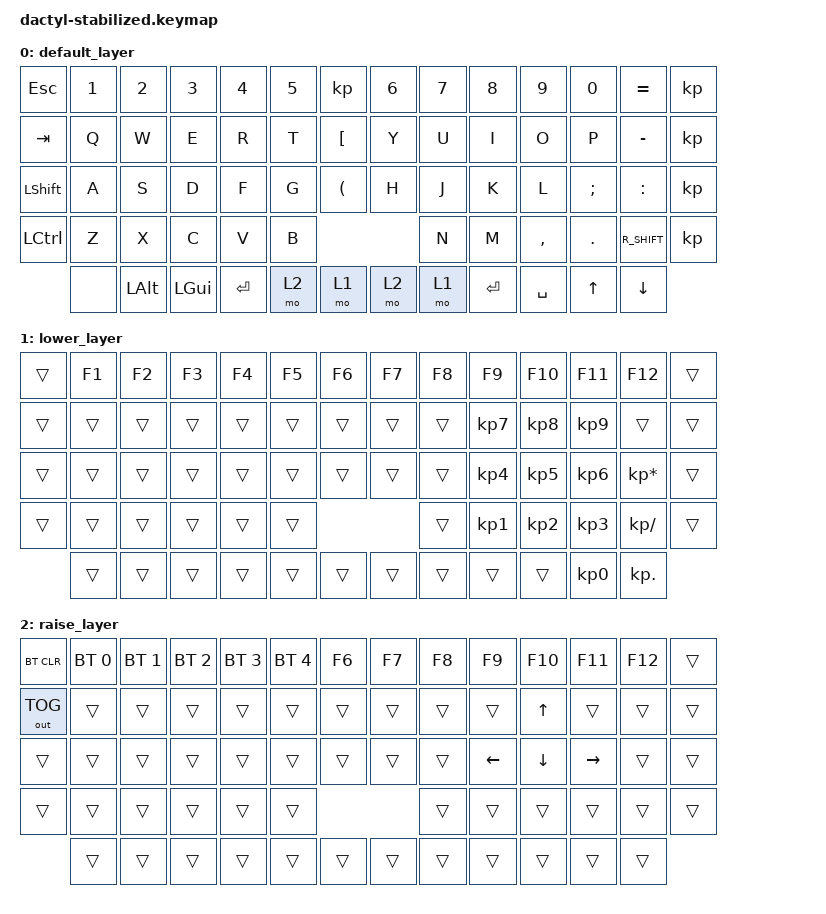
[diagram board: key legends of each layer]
/*
 * Copyright (c) 2020 The ZMK Contributors
 *
 * SPDX-License-Identifier: MIT
 */

 #include <behaviors.dtsi>
 #include <dt-bindings/zmk/keys.h>
 #include <dt-bindings/zmk/bt.h>
 #include <dt-bindings/zmk/outputs.h>
 
 / {
     keymap {
         compatible = "zmk,keymap";
 
         // TODO: SWAP SHIFTED KEYS SOMEHOW
         default_layer {
 // ------------------------------------------------------------------------------------------------------------
 // |  ESC  |  1  |  2  |   3  |   4   |   5   |       |  |   6   |   7   |  8    |  9    |  0   |   =   |       |
 // |  TAB  |  Q  |  W  |   E  |   R   |   T   |       |  |   Y   |   U   |  I    |  O    |  P   |   -   |       |
 // | SHIFT |  A  |  S  |   D  |   F   |   G   |       |  |   H   |   J   |  K    |  L    |  ;   |   '   |       |
 // |  CTRL |  Z  |  X  |   C  |   V   |   B   |       |  |   N   |   M   |  ,    |  .    |  /   | Shift |       |
 //         | LEFT|RIGHT| BSPC |  DEL  |       |       |  | RAISE | LOWER | ENTER | SPACE |  UP  |   DO  |

 bindings = <
 &kp ESC    &kp 1    &kp 2    &kp 3    &kp 4      &kp 5     &kp                &kp 6       &kp 7     &kp 8     &kp 9     &kp 0       &kp EQUAL   &kp 
 &kp TAB    &kp Q    &kp W    &kp E    &kp R      &kp T     &kp LBKT           &kp Y       &kp U     &kp I     &kp O     &kp P       &kp MINUS   &kp 
 &kp LSHFT  &kp A    &kp S    &kp D    &kp F      &kp G     &kp LPAR           &kp H       &kp J     &kp K     &kp L     &kp SEMI    &kp COLON   &kp 
 &kp LCTRL  &kp Z    &kp X    &kp C    &kp V      &kp B                                    &kp N     &kp M     &kp COMMA &kp DOT     &kp R_SHIFT &kp 
            &none    &kp LALT &kp LGUI &kp ENTER  &mo 2     &mo 1              &mo 2       &mo 1     &kp ENTER &kp SPACE &kp UP   &kp DOWN
             >;
 
             sensor-bindings = <&inc_dec_kp C_VOL_UP C_VOL_DN &inc_dec_kp PG_UP PG_DN>;
         };
 
         lower_layer {
 // ------------------------------------------------------------------------------------------------------------
 // |       |  F1 | F2  |  F3  |  F4  |  F5  |   F6   |  |       |  F7  |  F8   |  F9   |  F10  |  F11  |  F12  |       |
 // |       |     |     |      |      |      |        |  |       |      |   7   |   8   |   9   |       |       |       |
 // |       |     |     |      |      |      |        |  |       |      |   4   |   5   |   6   |   *   |       |       |
 // |       |     |     |      |      |      |        |  |       |      |   1   |   2   |   3   |   /   |       |       |
 //               |     |      |      |      |        |  |       |      |       |       |       |   0   |   .   |       |
             bindings = <
 &trans    &kp F1    &kp F2    &kp F3    &kp F4    &kp F5    &kp F6          &kp F7   &kp F8     &kp F9    &kp F10   &kp F11   &kp F12         &trans
 &trans    &trans    &trans    &trans    &trans    &trans    &trans          &trans    &trans    &kp KP_N7 &kp KP_N8 &kp KP_N9 &trans          &trans
 &trans    &trans    &trans    &trans    &trans    &trans    &trans          &trans    &trans    &kp KP_N4 &kp KP_N5 &kp KP_N6 &kp KP_MULTIPLY &trans
 &trans    &trans    &trans    &trans    &trans    &trans                              &trans    &kp KP_N1 &kp KP_N2 &kp KP_N3 &kp KP_DIVIDE   &trans
           &trans    &trans    &trans    &trans    &trans    &trans          &trans    &trans    &trans    &trans    &kp KP_N0 &kp KP_DOT
             >;
         };
 
         raise_layer {
 // ------------------------------------------------------------------------------------------------------------
 // |       |  F1 | F2  |  F3  |  F4  |  F5  |   F6   |  |       |  F7  |  F8   |  F9   |  F10 |  F11  |  F12  |
 // |       |     |     |      |      |      |        |  |       |      |   ^   |       |      |       |       |
 // |       |     |     |      |      |      |        |  |       |  <   |   v   |   >   |      |       |       |
 // |       |     |     |      |      |      |        |  |       |      |       |       |      |       |       |
 //               |     |      |      |      |        |  |       |      |       |       |      |       |       |
             bindings = <
 &bt BT_CLR   &bt BT_SEL 0 &bt BT_SEL 1 &bt BT_SEL 2 &bt BT_SEL 3 &bt BT_SEL 4 &kp F6          &kp F7   &kp F8     &kp F9    &kp F10  &kp F11   &kp F12   &trans
 &out OUT_TOG &trans       &trans       &trans       &trans       &trans       &trans          &trans    &trans    &trans    &kp UP   &trans    &trans    &trans
 &trans       &trans       &trans       &trans       &trans       &trans       &trans          &trans    &trans    &kp LEFT  &kp DOWN &kp RIGHT &trans    &trans
 &trans       &trans       &trans       &trans       &trans       &trans                                 &trans    &trans    &trans    &trans    &trans    &trans
              &trans       &trans       &trans       &trans       &trans       &trans          &trans    &trans    &trans    &trans    &trans    &trans
             >;
         };
     };
 };
